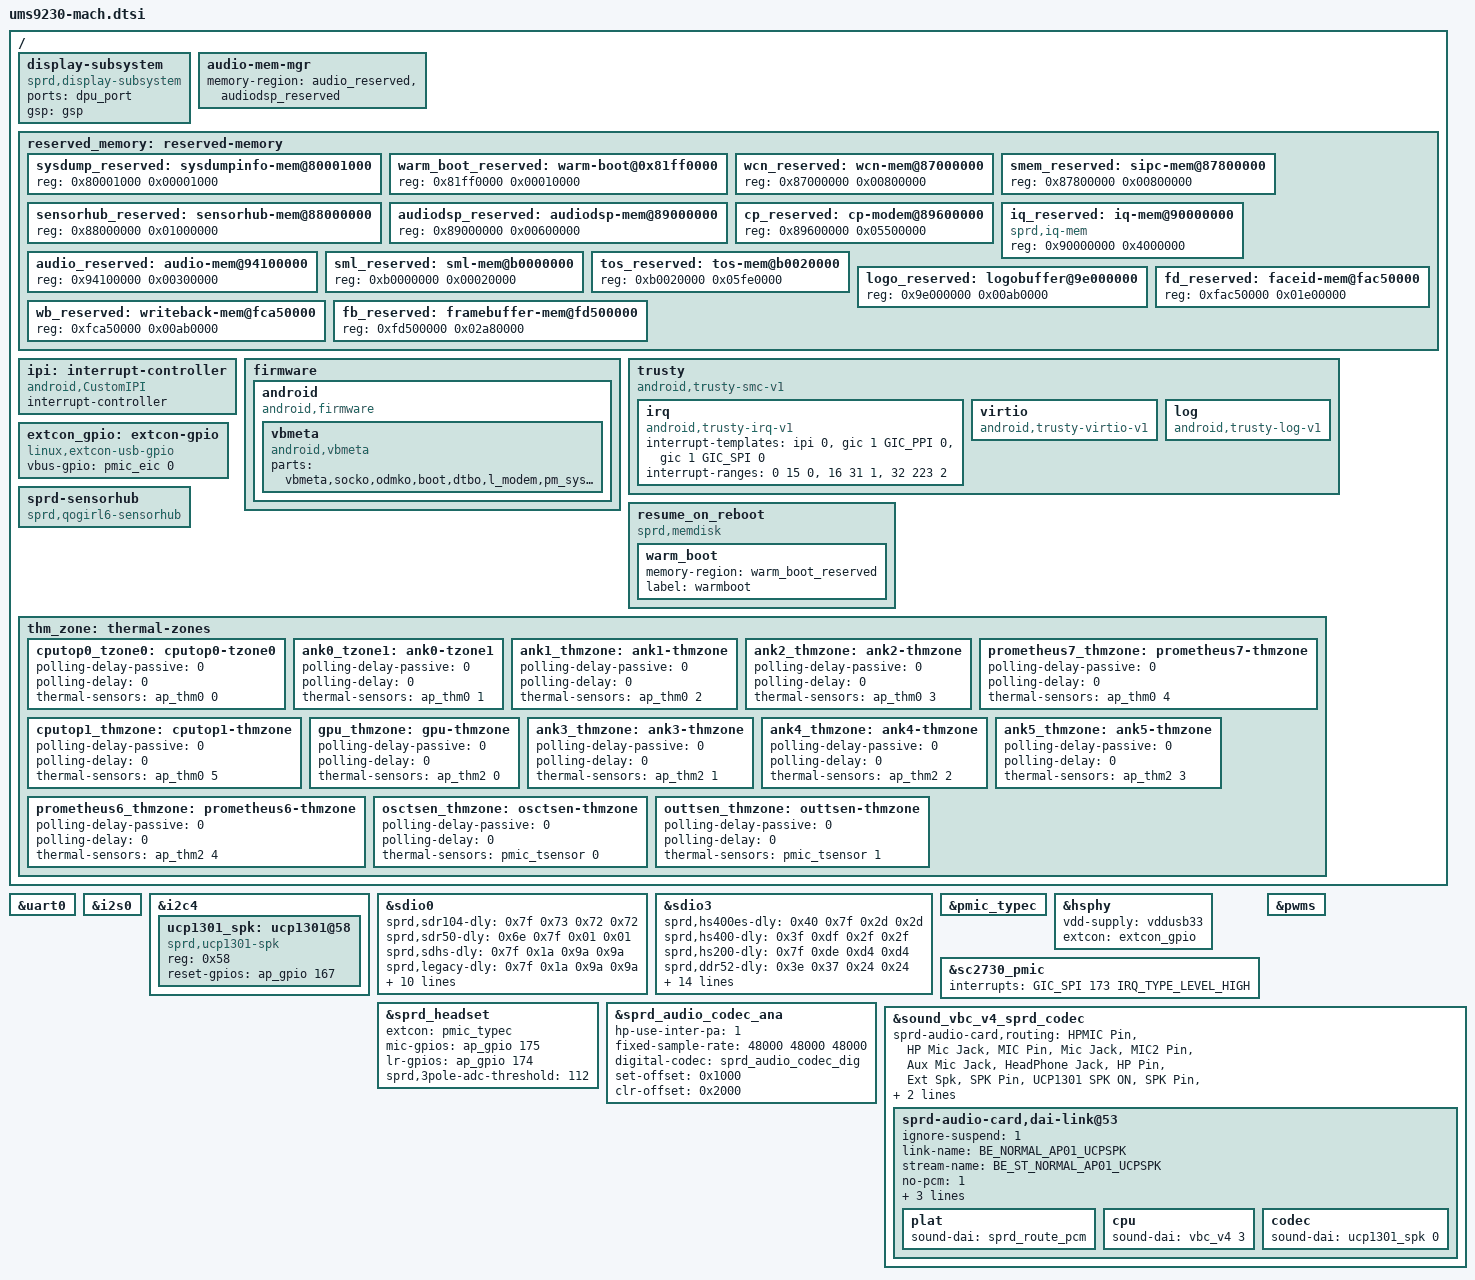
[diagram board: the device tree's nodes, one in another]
/*
 * Spreadtrum Qogirl6 board common DTS file
 *
 * Copyright (C) 2020, Spreadtrum Communications Inc.
 *
 * This file is licensed under a dual GPLv2 or X11 license.
 */


/{
	display-subsystem {
		compatible = "sprd,display-subsystem";
		ports = <&dpu_port>;
		gsp = <&gsp>;
	};

	audio-mem-mgr {
		memory-region = <&audio_reserved &audiodsp_reserved>;
	};

	reserved_memory: reserved-memory {
		#address-cells = <1>;
		#size-cells = <1>;
		ranges;

		sysdump_reserved: sysdumpinfo-mem@80001000 {
			reg = <0x80001000 0x00001000>;
		};

		warm_boot_reserved: warm-boot@0x81ff0000 {
			reg = <0x81ff0000 0x00010000>; /* 64K */
		};

		wcn_reserved: wcn-mem@87000000 {
			reg = <0x87000000 0x00800000>;
		};

		/* must be 64M aligned */
		smem_reserved: sipc-mem@87800000{
			reg = <0x87800000 0x00800000>;
		};

		sensorhub_reserved: sensorhub-mem@88000000 {
			reg = <0x88000000 0x01000000>;
		};

		audiodsp_reserved: audiodsp-mem@89000000 {
			reg = <0x89000000 0x00600000>;
		};

		cp_reserved: cp-modem@89600000 {
			reg = <0x89600000 0x05500000>;
		};

		/* Only used for iq, will be removed in normal mode by uboot */
		iq_reserved: iq-mem@90000000{
			compatible = "sprd,iq-mem";
			reg = <0x90000000 0x4000000>;
		};

		audio_reserved: audio-mem@94100000 {
			reg = <0x94100000 0x00300000>;
		};

		sml_reserved: sml-mem@b0000000 {
			reg = <0xb0000000 0x00020000>;
		};

		tos_reserved: tos-mem@b0020000 {
			reg = <0xb0020000 0x05fe0000>;
		};

		logo_reserved: logobuffer@9e000000{
			reg = <0x9e000000 0x00ab0000>;
		};

		fd_reserved: faceid-mem@fac50000 {
			reg = <0xfac50000 0x01e00000>;
		};

		wb_reserved: writeback-mem@fca50000 {
			reg = <0xfca50000 0x00ab0000>;
		};

		fb_reserved: framebuffer-mem@fd500000 {
			reg = <0xfd500000 0x02a80000>;
		};
	};

	ipi: interrupt-controller {
		compatible = "android,CustomIPI";
		#interrupt-cells = <1>;
		interrupt-controller;
	};

	firmware {
		android {
			compatible = "android,firmware";
			vbmeta {
				compatible = "android,vbmeta";
				parts = "vbmeta,socko,odmko,boot,dtbo,l_modem,pm_sys,l_ldsp,l_gdsp,l_agdsp";
			};
		};
	};

	trusty {
		compatible = "android,trusty-smc-v1";
		irq {
			compatible = "android,trusty-irq-v1";
			interrupt-templates = <&ipi 0>,
						<&gic 1 GIC_PPI 0>,
						<&gic 1 GIC_SPI 0>;
				interrupt-ranges = < 0  15 0>,
						<16  31 1>,
						<32 223 2>;
		};

		virtio {
			compatible = "android,trusty-virtio-v1";
		};

		log {
			compatible = "android,trusty-log-v1";
		};
	};

	resume_on_reboot {
		compatible = "sprd,memdisk";

		warm_boot {
			memory-region = <&warm_boot_reserved>;
				label = "warmboot";
		};
	};

	extcon_gpio: extcon-gpio {
		compatible = "linux,extcon-usb-gpio";
		vbus-gpio = <&pmic_eic 0 GPIO_ACTIVE_HIGH>;
	};

	sprd-sensorhub {
		 compatible = "sprd,qogirl6-sensorhub", "sprd,sensor-hub";
	};

	thm_zone: thermal-zones {
		cputop0_tzone0: cputop0-tzone0 {
			polling-delay-passive = <0>;
			polling-delay = <0>;
			thermal-sensors = <&ap_thm0 0>;
		};

		ank0_tzone1: ank0-tzone1 {
			polling-delay-passive = <0>;
			polling-delay = <0>;
			thermal-sensors = <&ap_thm0 1>;
		};

		ank1_thmzone: ank1-thmzone {
			polling-delay-passive = <0>;
			polling-delay = <0>;
			thermal-sensors = <&ap_thm0 2>;
		};

		ank2_thmzone: ank2-thmzone {
			polling-delay-passive = <0>;
			polling-delay = <0>;
			thermal-sensors = <&ap_thm0 3>;
		};

		prometheus7_thmzone: prometheus7-thmzone {
			polling-delay-passive = <0>;
			polling-delay = <0>;
			thermal-sensors = <&ap_thm0 4>;
		};

		cputop1_thmzone: cputop1-thmzone {
			polling-delay-passive = <0>;
			polling-delay = <0>;
			thermal-sensors = <&ap_thm0 5>;
		};

		gpu_thmzone: gpu-thmzone {
			polling-delay-passive = <0>;
			polling-delay = <0>;
			thermal-sensors = <&ap_thm2 0>;
		};

		ank3_thmzone: ank3-thmzone {
			polling-delay-passive = <0>;
			polling-delay = <0>;
			thermal-sensors = <&ap_thm2 1>;
		};

		ank4_thmzone: ank4-thmzone {
			polling-delay-passive = <0>;
			polling-delay = <0>;
			thermal-sensors = <&ap_thm2 2>;
		};

		ank5_thmzone: ank5-thmzone {
			polling-delay-passive = <0>;
			polling-delay = <0>;
			thermal-sensors = <&ap_thm2 3>;
		};

		prometheus6_thmzone: prometheus6-thmzone {
			polling-delay-passive = <0>;
			polling-delay = <0>;
			thermal-sensors = <&ap_thm2 4>;
		};

		osctsen_thmzone: osctsen-thmzone {
			 polling-delay-passive = <0>;
			 polling-delay = <0>;
			 thermal-sensors = <&pmic_tsensor 0>;
		 };

		outtsen_thmzone: outtsen-thmzone {
			 polling-delay-passive = <0>;
			 polling-delay = <0>;
			 thermal-sensors = <&pmic_tsensor 1>;
		 };
	};
};

&uart0 {
	status = "okay";
};

&i2s0 {
	status = "okay";
};

&i2c4 {
	ucp1301_spk: ucp1301@58 {
		compatible = "sprd,ucp1301-spk";
		reg = <0x58>;
		reset-gpios = <&ap_gpio 167 GPIO_ACTIVE_HIGH>;
		#sound-dai-cells = <1>;
	};
};

&sdio0 {
	sprd,sdr104-dly = <0x7f 0x73 0x72 0x72>;
	sprd,sdr50-dly = <0x6e 0x7f 0x01 0x01>;
	sprd,sdhs-dly = <0x7f 0x1a 0x9a 0x9a>;
	sprd,legacy-dly = <0x7f 0x1a 0x9a 0x9a>;
	vmmc-supply = <&vddsdcore>;
	vqmmc-supply = <&vddsdio>;
	voltage-ranges = <3000 3000>;
	bus-width = <4>;
	sd-uhs-sdr104;
	sd-uhs-sdr50;
	sprd,name = "sdio_sd";
	sprd,sdio-adma;
	no-sdio;
	no-mmc;
	status = "okay";
};

&sdio3 {
	sprd,hs400es-dly = <0x40 0x7f 0x2d 0x2d>;
	sprd,hs400-dly = <0x3f 0xdf 0x2f 0x2f>;
	sprd,hs200-dly = <0x7f 0xde 0xd4 0xd4>;
	sprd,ddr52-dly = <0x3e 0x37 0x24 0x24>;
	sprd,mmchs-dly = <0x60 0xb7 0x34 0x34>;
	vmmc-supply = <&vddemmccore>;
	voltage-ranges = <3000 3000>;
	bus-width = <8>;
	non-removable;
	cap-mmc-hw-reset;
	mmc-hs400-enhanced-strobe;
	mmc-hs400-1_8v;
	mmc-hs200-1_8v;
	mmc-ddr-1_8v;
	sprd,name = "sdio_emmc";
	sprd,sdio-adma;
	no-sdio;
	no-sd;
	status = "okay";
};

&pmic_typec {
	status = "okay";
};

&hsphy {
	vdd-supply = <&vddusb33>;
	extcon = <&extcon_gpio>;
};

&sc2730_pmic {
	interrupts = <GIC_SPI 173 IRQ_TYPE_LEVEL_HIGH>;
};

&pwms {
	status = "okay";
};

&sprd_headset {
	status = "okay";
	extcon = <&pmic_typec>;
	mic-gpios = <&ap_gpio 175 GPIO_ACTIVE_HIGH>;
	lr-gpios = <&ap_gpio 174 GPIO_ACTIVE_HIGH>;
	sprd,3pole-adc-threshold = <112>;
};

&sprd_audio_codec_ana {
	status = "okay";
	hp-use-inter-pa = <1>;
	fixed-sample-rate = <48000 48000 48000>;
	digital-codec = <&sprd_audio_codec_dig>;
	set-offset = <0x1000>;
	clr-offset = <0x2000>;
};

&sound_vbc_v4_sprd_codec {
	status = "okay";
	sprd-audio-card,routing =
		"HPMIC Pin", "HP Mic Jack",
		"MIC Pin", "Mic Jack",
		"MIC2 Pin", "Aux Mic Jack",
		"HeadPhone Jack", "HP Pin",
		"Ext Spk", "SPK Pin",
		"UCP1301 SPK ON", "SPK Pin",
		"Ext Spk", "UCP1301 SPK",
		"DMIC Pin", "DMic Jack",
		"DMIC1 Pin", "DMic1 Jack",
		"Ext Ear", "EAR Pin";

	/* 35: ucp1301 normal ap01 */
	sprd-audio-card,dai-link@53 {
		ignore-suspend = <1>;
		link-name = "BE_NORMAL_AP01_UCPSPK";
		stream-name = "BE_ST_NORMAL_AP01_UCPSPK";
		no-pcm = <1>;
		dpcm-playback = <1>;
		be-id = <0>;
		dai-format = "i2s";
		plat {
			sound-dai = <&sprd_route_pcm>;
		};
		cpu {
			sound-dai = <&vbc_v4 3>;
		};
		codec {
			sound-dai = <&ucp1301_spk 0>;
		};
	};
	/*
	 * node 54 and node 55 (index 36 and 37) are reserved for
	 * "ucp1301-spk2" and "ucp1301-rcv"
	 * nodes from 56 to 67 (index from 38 to 49) are used by HIFI
	 */
};
